VERSION ""
NS_ :

BS_:

BU_: DCM FSM JSONCANTest

BO_ 200 DCM_VITALS: 1 DCM
SG_ HEARTBEAT : 0|1@1+ (1,0) [0|1] "" DEBUG

BO_ 201 DCM_CAN_FIFO_OVERFLOW: 8 DCM
SG_ tx_overflow_count : 0|32@1+ (1,0) [0|4294967295] "" DEBUG
SG_ rx_overflow_count : 32|32@1+ (1,0) [0|4294967295] "" DEBUG

BO_ 203 DCM_WATCHDOG_TIMEOUT: 4 DCM
SG_ TASK_NAME : 0|32@1+ (1,0) [0|4294967295] "" DEBUG

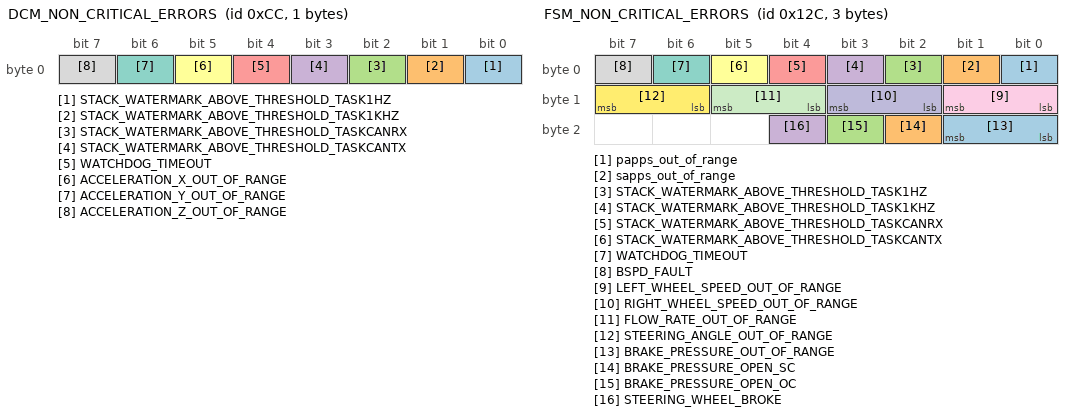
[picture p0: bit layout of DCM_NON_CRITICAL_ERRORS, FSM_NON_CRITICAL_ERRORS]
BO_ 204 DCM_NON_CRITICAL_ERRORS: 1 DCM
SG_ STACK_WATERMARK_ABOVE_THRESHOLD_TASK1HZ : 0|1@1+ (1,0) [0|1] "" DEBUG
SG_ STACK_WATERMARK_ABOVE_THRESHOLD_TASK1KHZ : 1|1@1+ (1,0) [0|1] "" DEBUG
SG_ STACK_WATERMARK_ABOVE_THRESHOLD_TASKCANRX : 2|1@1+ (1,0) [0|1] "" DEBUG
SG_ STACK_WATERMARK_ABOVE_THRESHOLD_TASKCANTX : 3|1@1+ (1,0) [0|1] "" DEBUG
SG_ WATCHDOG_TIMEOUT : 4|1@1+ (1,0) [0|1] "" DEBUG
SG_ ACCELERATION_X_OUT_OF_RANGE : 5|1@1+ (1,0) [0|1] "" DEBUG
SG_ ACCELERATION_Y_OUT_OF_RANGE : 6|1@1+ (1,0) [0|1] "" DEBUG
SG_ ACCELERATION_Z_OUT_OF_RANGE : 7|1@1+ (1,0) [0|1] "" DEBUG

BO_ 205 DCM_STATE_MACHINE: 1 DCM
SG_ State : 0|8@1+ (1,0) [0|255] "" DEBUG

BO_ 207 DCM_AIR_SHUTDOWN_ERRORS: 1 DCM
SG_ MISSING_HEARTBEAT : 0|1@1+ (1,0) [0|1] "" DEBUG

BO_ 208 DCM_MOTOR_SHUTDOWN_ERRORS: 1 DCM
SG_ MISSING_HEARTBEAT : 0|1@1+ (1,0) [0|1] "" DEBUG

BO_ 212 DCM_INVERTER_SWITCHES: 1 DCM
SG_ Right_Inverter_Switch : 0|1@1+ (1,0) [0|1] "" DEBUG
SG_ Left_Inverter_Switch : 1|1@1+ (1,0) [0|1] "" DEBUG

BO_ 13 FSM_PEDAL_POSITION: 4 FSM
SG_ Mapped_Pedal_Percentage : 0|32@1+ (2.3283064370807974e-08,0) [0|100] "%" DEBUG

BO_ 90 FSM_Torque_Limiting: 4 FSM
SG_ FSM_Torque_Limit : 0|32@1+ (3.492459655621196e-08,0) [0|150] "nM" DEBUG

BO_ 151 FSM_APPS: 8 FSM
SG_ Papps_Mapped_Pedal_Percentage : 0|32@1+ (2.3283064370807974e-08,0) [0|100] "%" DEBUG,JSONCANTest
SG_ Sapps_Mapped_Pedal_Percentage : 32|32@1+ (2.3283064370807974e-08,0) [0|100] "%" DEBUG,JSONCANTest

BO_ 300 FSM_NON_CRITICAL_ERRORS: 3 FSM
SG_ papps_out_of_range : 0|1@1+ (1,0) [0|1] "" DEBUG,JSONCANTest
SG_ sapps_out_of_range : 1|1@1+ (1,0) [0|1] "" DEBUG,JSONCANTest
SG_ STACK_WATERMARK_ABOVE_THRESHOLD_TASK1HZ : 2|1@1+ (1,0) [0|1] "" DEBUG,JSONCANTest
SG_ STACK_WATERMARK_ABOVE_THRESHOLD_TASK1KHZ : 3|1@1+ (1,0) [0|1] "" DEBUG,JSONCANTest
SG_ STACK_WATERMARK_ABOVE_THRESHOLD_TASKCANRX : 4|1@1+ (1,0) [0|1] "" DEBUG,JSONCANTest
SG_ STACK_WATERMARK_ABOVE_THRESHOLD_TASKCANTX : 5|1@1+ (1,0) [0|1] "" DEBUG,JSONCANTest
SG_ WATCHDOG_TIMEOUT : 6|1@1+ (1,0) [0|1] "" DEBUG,JSONCANTest
SG_ BSPD_FAULT : 7|1@1+ (1,0) [0|1] "" DEBUG,JSONCANTest
SG_ LEFT_WHEEL_SPEED_OUT_OF_RANGE : 8|2@1+ (1,0) [0|3] "" DEBUG,JSONCANTest
SG_ RIGHT_WHEEL_SPEED_OUT_OF_RANGE : 10|2@1+ (1,0) [0|3] "" DEBUG,JSONCANTest
SG_ FLOW_RATE_OUT_OF_RANGE : 12|2@1+ (1,0) [0|3] "" DEBUG,JSONCANTest
SG_ STEERING_ANGLE_OUT_OF_RANGE : 14|2@1+ (1,0) [0|3] "" DEBUG,JSONCANTest
SG_ BRAKE_PRESSURE_OUT_OF_RANGE : 16|2@1+ (1,0) [0|3] "" DEBUG,JSONCANTest
SG_ BRAKE_PRESSURE_OPEN_SC : 18|1@1+ (1,0) [0|1] "" DEBUG,JSONCANTest
SG_ BRAKE_PRESSURE_OPEN_OC : 19|1@1+ (1,0) [0|1] "" DEBUG,JSONCANTest
SG_ STEERING_WHEEL_BROKE : 20|1@1+ (1,0) [0|1] "" DEBUG,JSONCANTest

BO_ 301 FSM_VITALS: 1 FSM
SG_ HEARTBEAT : 0|1@1+ (1,0) [0|1] "" DEBUG

BO_ 302 FSM_CAN_FIFO_OVERFLOW: 8 FSM
SG_ tx_overflow_count : 0|32@1+ (1,0) [0|4294967295] "" DEBUG
SG_ rx_overflow_count : 32|32@1+ (1,0) [0|4294967295] "" DEBUG

BO_ 304 FSM_WATCHDOG_TIMEOUT: 1 FSM
SG_ TASK_NAME : 0|8@1+ (1,0) [0|255] "" DEBUG

BO_ 305 FSM_STATE_MACHINE: 1 FSM
SG_ State : 0|8@1+ (1,0) [0|255] "" DEBUG

BO_ 307 FSM_FLOW_METER: 1 FSM
SG_ FLOW_RATE : 0|8@1+ (0.39215686274509803,0) [0|100] "L/min" DEBUG

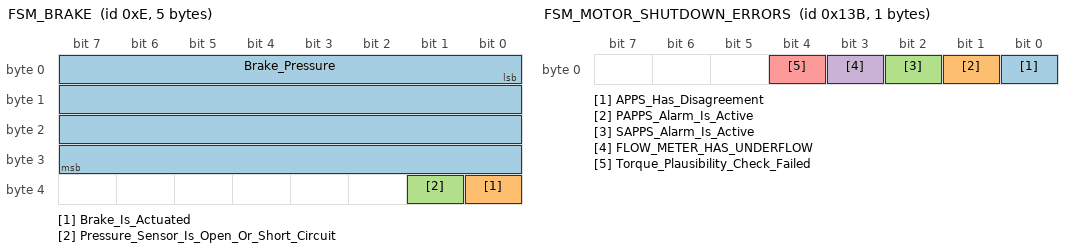
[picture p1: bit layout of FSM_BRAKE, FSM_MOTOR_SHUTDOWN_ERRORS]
BO_ 14 FSM_BRAKE: 5 FSM
SG_ Brake_Pressure : 0|32@1+ (5.820766092701993e-07,0) [0|2500] "psi" DEBUG
SG_ Brake_Is_Actuated : 32|1@1+ (1,0) [0|1] "" DEBUG
SG_ Pressure_Sensor_Is_Open_Or_Short_Circuit : 33|1@1+ (1,0) [0|1] "" DEBUG

BO_ 310 FSM_AIR_SHUTDOWN_ERRORS: 1 FSM
SG_ MISSING_HEARTBEAT : 0|1@1+ (1,0) [0|1] "" DEBUG

BO_ 315 FSM_MOTOR_SHUTDOWN_ERRORS: 1 FSM
SG_ APPS_Has_Disagreement : 0|1@1+ (1,0) [0|1] "" DEBUG
SG_ PAPPS_Alarm_Is_Active : 1|1@1+ (1,0) [0|1] "" DEBUG
SG_ SAPPS_Alarm_Is_Active : 2|1@1+ (1,0) [0|1] "" DEBUG
SG_ FLOW_METER_HAS_UNDERFLOW : 3|1@1+ (1,0) [0|1] "" DEBUG
SG_ Torque_Plausibility_Check_Failed : 4|1@1+ (1,0) [0|1] "" DEBUG

BO_ 317 FSM_WHEEL_SPEED_SENSOR: 4 FSM
SG_ Left_Wheel_Speed : 0|16@1+ (0.0022888532845044634,0) [0|150] "km/h" DEBUG
SG_ Right_Wheel_Speed : 32|16@1+ (0.0022888532845044634,0) [0|150] "km/h" DEBUG

BO_ 318 FSM_STEERING_ANGLE_SENSOR: 4 FSM
SG_ Steering_Angle : 0|32@1+ (5.122274161577754e-08,-110) [-110|110] "km/h" DEBUG

BO_ 601 JSONCANTest_VITALS: 5 JSONCANTest
SG_ HEARTBEAT : 0|1@1+ (1.0,0) [0|1] "" DEBUG
SG_ TIMESTAMP : 1|32@1+ (1,0) [0|4294967295] "" DEBUG

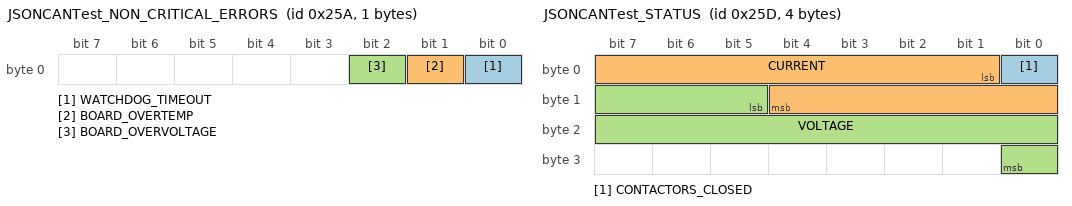
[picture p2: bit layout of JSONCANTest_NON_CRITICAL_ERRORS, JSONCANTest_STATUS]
BO_ 602 JSONCANTest_NON_CRITICAL_ERRORS: 1 JSONCANTest
SG_ WATCHDOG_TIMEOUT : 0|1@1+ (1,0) [0|1] "" DEBUG
SG_ BOARD_OVERTEMP : 1|1@1+ (1,0) [0|1] "" DEBUG
SG_ BOARD_OVERVOLTAGE : 2|1@1+ (1,0) [0|1] "" DEBUG

BO_ 603 JSONCANTest_AIR_SHUTDOWN_ERRORS: 1 JSONCANTest
SG_ DUMMY_AIR_SHUTDOWN : 0|1@1+ (1,0) [0|1] "" DEBUG

BO_ 604 JSONCANTest_MOTOR_SHUTDOWN_ERRORS: 1 JSONCANTest
SG_ DUMMY_MOTOR_SHUTDOWN : 0|1@1+ (1,0) [0|1] "" DEBUG

BO_ 605 JSONCANTest_STATUS: 4 JSONCANTest
SG_ CONTACTORS_CLOSED : 0|1@1+ (1,0) [0|1] "" DEBUG
SG_ CURRENT : 1|12@1+ (0.02442002442002442,0) [0|100] "A" DEBUG
SG_ VOLTAGE : 13|12@1+ (0.1221001221001221,0) [0|500] "V" DEBUG

BA_DEF_  "BusType" STRING ;
BA_DEF_ BO_  "GenMsgCycleTime" INT 0 65535;
BA_DEF_ SG_  "GenSigStartValue" INT 0 2147483647;

BA_DEF_DEF_  "BusType" "CAN";
BA_DEF_DEF_  "GenMsgCycleTime" 0;
BA_DEF_DEF_  "GenSigStartValue" 0;

BA_ "GenSigStartValue" SG_ 605 CURRENT 50;

BA_ "GenMsgCycleTime" BO_ 200  1000;
BA_ "GenMsgCycleTime" BO_ 201  1000;
BA_ "GenMsgCycleTime" BO_ 203  10000;
BA_ "GenMsgCycleTime" BO_ 204  1000;
BA_ "GenMsgCycleTime" BO_ 205  1000;
BA_ "GenMsgCycleTime" BO_ 207  1000;
BA_ "GenMsgCycleTime" BO_ 208  1000;
BA_ "GenMsgCycleTime" BO_ 212  1000;
BA_ "GenMsgCycleTime" BO_ 13  1000;
BA_ "GenMsgCycleTime" BO_ 90  1000;
BA_ "GenMsgCycleTime" BO_ 151  1000;
BA_ "GenMsgCycleTime" BO_ 300  100;
BA_ "GenMsgCycleTime" BO_ 301  1000;
BA_ "GenMsgCycleTime" BO_ 302  1000;
BA_ "GenMsgCycleTime" BO_ 304  10000;
BA_ "GenMsgCycleTime" BO_ 305  1000;
BA_ "GenMsgCycleTime" BO_ 307  1000;
BA_ "GenMsgCycleTime" BO_ 14  1000;
BA_ "GenMsgCycleTime" BO_ 310  1000;
BA_ "GenMsgCycleTime" BO_ 315  1000;
BA_ "GenMsgCycleTime" BO_ 317  1000;
BA_ "GenMsgCycleTime" BO_ 318  1000;
BA_ "GenMsgCycleTime" BO_ 601  1000;
BA_ "GenMsgCycleTime" BO_ 602  1000;
BA_ "GenMsgCycleTime" BO_ 603  1000;
BA_ "GenMsgCycleTime" BO_ 604  1000;
BA_ "GenMsgCycleTime" BO_ 605  1000;

VAL_ 200 HEARTBEAT 0 "FALSE"1 "TRUE";
VAL_ 301 HEARTBEAT 0 "FALSE"1 "TRUE";
VAL_ 605 CONTACTORS_CLOSED 0 "AIR_OPEN"1 "AIR_CLOSED";
